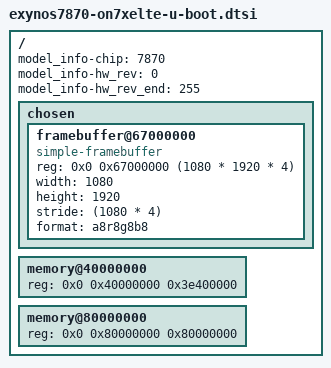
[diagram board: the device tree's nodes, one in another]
// SPDX-License-Identifier: GPL-2.0
/*
 * Copyright (c) 2026 Kaustabh Chakraborty <kauschluss@disroot.org>
 */

/ {
	/* These properties are required by S-BOOT. */
	model_info-chip = <7870>;
	model_info-hw_rev = <0>;
	model_info-hw_rev_end = <255>;

	chosen {
		#address-cells = <2>;
		#size-cells = <1>;
		ranges;

		framebuffer@67000000 {
			compatible = "simple-framebuffer";
			reg = <0x0 0x67000000 (1080 * 1920 * 4)>;
			width = <1080>;
			height = <1920>;
			stride = <(1080 * 4)>;
			format = "a8r8g8b8";
		};
	};

	/*
	 * S-BOOT will populate the memory nodes stated below. Existing
	 * values redefine the safe memory requirements as stated in upstream
	 * device tree, in separate nodes for each bank.
	 */
	memory@40000000 {
		device_type = "memory";
		reg = <0x0 0x40000000 0x3e400000>;
	};

	memory@80000000 {
		device_type = "memory";
		reg = <0x0 0x80000000 0x80000000>;
	};
};
